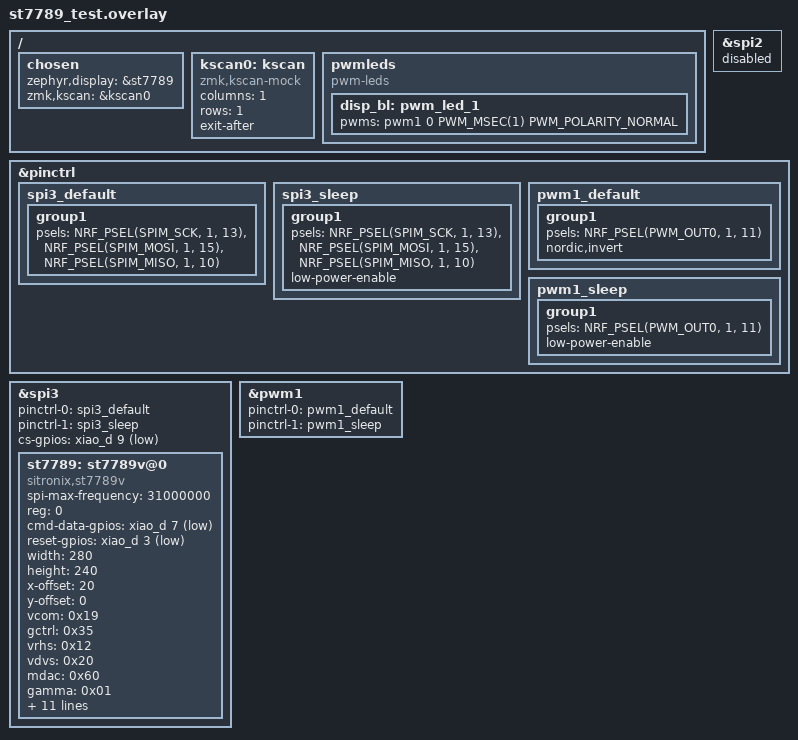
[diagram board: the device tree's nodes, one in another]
/*
 * ST7789 Color Display Test Shield
 * Tests full color display capabilities
 */

/ {
    chosen {
        zephyr,display = &st7789;
        zmk,kscan = &kscan0;
    };

    // Mock kscan for display-only test
    kscan0: kscan {
        compatible = "zmk,kscan-mock";
        columns = <1>;
        rows = <1>;
        exit-after;
    };

    // Backlight PWM
    pwmleds {
        compatible = "pwm-leds";
        disp_bl: pwm_led_1 {
            pwms = <&pwm1 0 PWM_MSEC(1) PWM_POLARITY_NORMAL>;
        };
    };
};

// Disable conflicting SPI2
&spi2 {
    status = "disabled";
};

// Pin configuration
&pinctrl {
    spi3_default: spi3_default {
        group1 {
            psels = <NRF_PSEL(SPIM_SCK, 1, 13)>,    // P1.13 = D8
                <NRF_PSEL(SPIM_MOSI, 1, 15)>,       // P1.15 = D10
                <NRF_PSEL(SPIM_MISO, 1, 10)>;       // Not used but required
        };
    };

    spi3_sleep: spi3_sleep {
        group1 {
            psels = <NRF_PSEL(SPIM_SCK, 1, 13)>,
                <NRF_PSEL(SPIM_MOSI, 1, 15)>,
                <NRF_PSEL(SPIM_MISO, 1, 10)>;
            low-power-enable;
        };
    };

    pwm1_default: pwm1_default {
        group1 {
            psels = <NRF_PSEL(PWM_OUT0, 1, 11)>;    // P1.11 = D6 (backlight)
            nordic,invert;
        };
    };

    pwm1_sleep: pwm1_sleep {
        group1 {
            psels = <NRF_PSEL(PWM_OUT0, 1, 11)>;
            low-power-enable;
        };
    };
};

// SPI3 for display
disp_spi: &spi3 {
    status = "okay";
    pinctrl-0 = <&spi3_default>;
    pinctrl-1 = <&spi3_sleep>;
    pinctrl-names = "default", "sleep";
    cs-gpios = <&xiao_d 9 GPIO_ACTIVE_LOW>;         // D9 = CS

    st7789: st7789v@0 {
        compatible = "sitronix,st7789v";
        spi-max-frequency = <31000000>;
        reg = <0>;
        cmd-data-gpios = <&xiao_d 7 GPIO_ACTIVE_LOW>;  // D7 = DC
        reset-gpios = <&xiao_d 3 GPIO_ACTIVE_LOW>;     // D3 = RST
        
        // 1.69" round display parameters
        width = <280>;
        height = <240>;
        x-offset = <20>;
        y-offset = <0>;
        
        // Color configuration
        vcom = <0x19>;
        gctrl = <0x35>;
        vrhs = <0x12>;
        vdvs = <0x20>;
        mdac = <0x60>;     // Display rotation
        gamma = <0x01>;
        colmod = <0x55>;   // 16-bit RGB565 color mode
        lcm = <0x2c>;
        porch-param = [ 0c 0c 00 33 33 ];
        cmd2en-param = [ 5a 69 02 01 ];
        pwctrl1-param = [ a4 a1 ];
        pvgam-param = [ D0 04 0D 11 13 2B 3F 54 4C 18 0D 0B 1F 23 ];
        nvgam-param = [ D0 04 0C 11 13 2C 3F 44 51 2F 1F 1F 20 23 ];
        ram-param = [ 00 F0 ];
        rgb-param = [ CD 08 14 ];
    };
};

// PWM for backlight control
&pwm1 {
    status = "okay";
    pinctrl-0 = <&pwm1_default>;
    pinctrl-1 = <&pwm1_sleep>;
    pinctrl-names = "default", "sleep";
};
